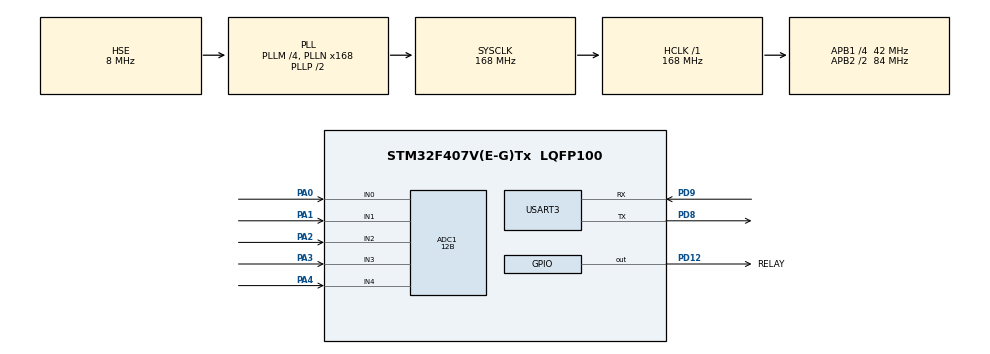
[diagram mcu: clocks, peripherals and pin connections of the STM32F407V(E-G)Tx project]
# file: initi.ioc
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ADC1.Channel-0\#ChannelRegularConversion=ADC_CHANNEL_0
ADC1.Channel-1\#ChannelRegularConversion=ADC_CHANNEL_1
ADC1.Channel-2\#ChannelRegularConversion=ADC_CHANNEL_2
ADC1.Channel-8\#ChannelRegularConversion=ADC_CHANNEL_3
ADC1.Channel-9\#ChannelRegularConversion=ADC_CHANNEL_4
ADC1.ClockPrescaler=ADC_CLOCK_SYNC_PCLK_DIV8
ADC1.ContinuousConvMode=ENABLE
ADC1.DMAContinuousRequests=ENABLE
ADC1.DataAlign=ADC_DATAALIGN_RIGHT
ADC1.DiscontinuousConvMode=DISABLE
ADC1.EOCSelection=ADC_EOC_SINGLE_CONV
ADC1.EnableAnalogWatchDog=false
ADC1.ExternalTrigConv=ADC_SOFTWARE_START
ADC1.ExternalTrigConvEdge=ADC_EXTERNALTRIGCONVEDGE_NONE
ADC1.InjNumberOfConversion=0
ADC1.NbrOfConversion=5
ADC1.NbrOfConversionFlag=1
ADC1.Rank-0\#ChannelRegularConversion=1
ADC1.Rank-1\#ChannelRegularConversion=2
ADC1.Rank-2\#ChannelRegularConversion=3
ADC1.Rank-8\#ChannelRegularConversion=4
ADC1.Rank-9\#ChannelRegularConversion=5
ADC1.Resolution=ADC_RESOLUTION_12B
ADC1.SamplingTime-0\#ChannelRegularConversion=ADC_SAMPLETIME_480CYCLES
ADC1.SamplingTime-1\#ChannelRegularConversion=ADC_SAMPLETIME_480CYCLES
ADC1.SamplingTime-2\#ChannelRegularConversion=ADC_SAMPLETIME_480CYCLES
ADC1.SamplingTime-8\#ChannelRegularConversion=ADC_SAMPLETIME_480CYCLES
ADC1.SamplingTime-9\#ChannelRegularConversion=ADC_SAMPLETIME_480CYCLES
ADC1.ScanConvMode=ENABLE
ADC1.master=1
Dma.ADC1.0.Direction=DMA_PERIPH_TO_MEMORY
Dma.ADC1.0.FIFOMode=DMA_FIFOMODE_DISABLE
Dma.ADC1.0.Instance=DMA2_Stream0
Dma.ADC1.0.MemDataAlignment=DMA_MDATAALIGN_HALFWORD
Dma.ADC1.0.MemInc=DMA_MINC_ENABLE
Dma.ADC1.0.Mode=DMA_CIRCULAR
Dma.ADC1.0.PeriphDataAlignment=DMA_PDATAALIGN_HALFWORD
Dma.ADC1.0.PeriphInc=DMA_PINC_DISABLE
Dma.ADC1.0.Priority=DMA_PRIORITY_LOW
Dma.Request0=ADC1
Mcu.Family=STM32F4
Mcu.Name=STM32F407V(E-G)Tx
Mcu.Package=LQFP100
NVIC.DMA2_Stream0_IRQn=true\:0\:0\:false\:false\:true\:false
NVIC.PriorityGroup=NVIC_PRIORITYGROUP_4
NVIC.TIM6_DAC_IRQn=true\:0\:0\:false\:false\:true\:true
NVIC.USART3_IRQn=true\:1\:0\:true\:false\:true\:true
PA0-WKUP.Signal=ADCx_IN0
PA1.Signal=ADCx_IN1
PA2.Signal=ADCx_IN2
PA3.Signal=ADCx_IN3
PA4.Signal=ADCx_IN4
PD12.GPIO_Label=RELAY
PD12.PinState=GPIO_PIN_SET
PD12.Signal=GPIO_Output
PD8.Mode=Asynchronous
PD8.Signal=USART3_TX
PD9.Mode=Asynchronous
PD9.Signal=USART3_RX
PH0-OSC_IN.Mode=HSE-External-Oscillator
PH0-OSC_IN.Signal=RCC_OSC_IN
PH1-OSC_OUT.Mode=HSE-External-Oscillator
PH1-OSC_OUT.Signal=RCC_OSC_OUT
ProjectManager.HeapSize=0x200
ProjectManager.StackSize=0x400
ProjectManager.TargetToolchain=MDK-ARM V5
RCC.48MHZClocksFreq_Value=84000000
RCC.AHBFreq_Value=168000000
RCC.APB1CLKDivider=RCC_HCLK_DIV4
RCC.APB1Freq_Value=42000000
RCC.APB1TimFreq_Value=84000000
RCC.APB2CLKDivider=RCC_HCLK_DIV2
RCC.APB2Freq_Value=84000000
RCC.APB2TimFreq_Value=168000000
RCC.CortexFreq_Value=168000000
RCC.HCLKFreq_Value=168000000
RCC.HSE_VALUE=8000000
RCC.HSI_VALUE=16000000
RCC.LSE_VALUE=32768
RCC.PLLM=4
RCC.PLLN=168
RCC.PLLSourceVirtual=RCC_PLLSOURCE_HSE
RCC.SYSCLKFreq_VALUE=168000000
RCC.SYSCLKSource=RCC_SYSCLKSOURCE_PLLCLK
RCC.VCOOutputFreq_Value=336000000
SH.ADCx_IN0.0=ADC1_IN0,IN0
SH.ADCx_IN1.0=ADC1_IN1,IN1
SH.ADCx_IN2.0=ADC1_IN2,IN2
SH.ADCx_IN3.0=ADC1_IN3,IN3
SH.ADCx_IN4.0=ADC1_IN4,IN4
TIM6.Period=20000
TIM6.Prescaler=41999
USART3.VirtualMode=VM_ASYNC
VP_TIM6_VS_ClockSourceINT.Mode=Enable_Timer
board=custom

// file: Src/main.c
/**
  ******************************************************************************
  * @file           : main.c
  * @brief          : Main program body
  ******************************************************************************
  ** This notice applies to any and all portions of this file
  * that are not between comment pairs USER CODE BEGIN and
  * USER CODE END. Other portions of this file, whether
  * inserted by the user or by software development tools
  * are owned by their respective copyright owners.
  *
  * COPYRIGHT(c) 2019 STMicroelectronics
  *
  * Redistribution and use in source and binary forms, with or without modification,
  * are permitted provided that the following conditions are met:
  *   1. Redistributions of source code must retain the above copyright notice,
  *      this list of conditions and the following disclaimer.
  *   2. Redistributions in binary form must reproduce the above copyright notice,
  *      this list of conditions and the following disclaimer in the documentation
  *      and/or other materials provided with the distribution.
  *   3. Neither the name of STMicroelectronics nor the names of its contributors
  *      may be used to endorse or promote products derived from this software
  *      without specific prior written permission.
  *
  * THIS SOFTWARE IS PROVIDED BY THE COPYRIGHT HOLDERS AND CONTRIBUTORS "AS IS"
  * AND ANY EXPRESS OR IMPLIED WARRANTIES, INCLUDING, BUT NOT LIMITED TO, THE
  * IMPLIED WARRANTIES OF MERCHANTABILITY AND FITNESS FOR A PARTICULAR PURPOSE ARE
  * DISCLAIMED. IN NO EVENT SHALL THE COPYRIGHT HOLDER OR CONTRIBUTORS BE LIABLE
  * FOR ANY DIRECT, INDIRECT, INCIDENTAL, SPECIAL, EXEMPLARY, OR CONSEQUENTIAL
  * DAMAGES (INCLUDING, BUT NOT LIMITED TO, PROCUREMENT OF SUBSTITUTE GOODS OR
  * SERVICES; LOSS OF USE, DATA, OR PROFITS; OR BUSINESS INTERRUPTION) HOWEVER
  * CAUSED AND ON ANY THEORY OF LIABILITY, WHETHER IN CONTRACT, STRICT LIABILITY,
  * OR TORT (INCLUDING NEGLIGENCE OR OTHERWISE) ARISING IN ANY WAY OUT OF THE USE
  * OF THIS SOFTWARE, EVEN IF ADVISED OF THE POSSIBILITY OF SUCH DAMAGE.
  *
  ******************************************************************************
  */
#include "main.h"
#include "stm32f4xx_hal.h"

ADC_HandleTypeDef hadc1;
DMA_HandleTypeDef hdma_adc1;

TIM_HandleTypeDef htim6;

UART_HandleTypeDef huart3;

/* USER CODE BEGIN PV */
/* Private variables ---------------------------------------------------------*/
//array in RAM for DMA-Controller to set values from ADC
volatile uint16_t adc_array[CHANNELS_NUMBER];
//buffer for messages of different length
uint8_t uart_rx_buf[UART_RX_BUF_SIZE];
/* USER CODE END PV */

void SystemClock_Config(void);
static void MX_GPIO_Init(void);
static void MX_DMA_Init(void);
static void MX_ADC1_Init(void);
static void MX_TIM6_Init(void);
static void MX_USART3_UART_Init(void);

/* USER CODE BEGIN PFP */
/* Private function prototypes -----------------------------------------------*/

/* USER CODE END PFP */

int main(void)
{

  /* MCU Configuration----------------------------------------------------------*/

  /* Reset of all peripherals, Initializes the Flash interface and the Systick. */
  HAL_Init();

  /* Configure the system clock */
  SystemClock_Config();

  /* Initialize all configured peripherals */
  MX_GPIO_Init();
  MX_DMA_Init();
  MX_ADC1_Init();
  MX_TIM6_Init();
  MX_USART3_UART_Init();
  /* USER CODE BEGIN 2 */
	//stat circular conversion
	HAL_ADC_Start_DMA(&hadc1, (uint32_t *) adc_array, CHANNELS_NUMBER);
	//enable IDLE interrupt to be able to detect the end of messages
	USART3->CR1 |= USART_CR1_IDLEIE;
	//start receiving to buffer
	HAL_UART_Receive_IT(&huart3, uart_rx_buf, UART_RX_BUF_SIZE);
  /* USER CODE END 2 */

  /* Infinite loop */
  while (1)
  {

  }

}

void SystemClock_Config(void)
{

  RCC_OscInitTypeDef RCC_OscInitStruct;
  RCC_ClkInitTypeDef RCC_ClkInitStruct;

    /**Configure the main internal regulator output voltage
    */
  __HAL_RCC_PWR_CLK_ENABLE();

  __HAL_PWR_VOLTAGESCALING_CONFIG(PWR_REGULATOR_VOLTAGE_SCALE1);

    /**Initializes the CPU, AHB and APB busses clocks
    */
  RCC_OscInitStruct.OscillatorType = RCC_OSCILLATORTYPE_HSE;
  RCC_OscInitStruct.HSEState = RCC_HSE_ON;
  RCC_OscInitStruct.PLL.PLLState = RCC_PLL_ON;
  RCC_OscInitStruct.PLL.PLLSource = RCC_PLLSOURCE_HSE;
  RCC_OscInitStruct.PLL.PLLM = 4;
  RCC_OscInitStruct.PLL.PLLN = 168;
  RCC_OscInitStruct.PLL.PLLP = RCC_PLLP_DIV2;
  RCC_OscInitStruct.PLL.PLLQ = 4;
  if (HAL_RCC_OscConfig(&RCC_OscInitStruct) != HAL_OK)
  {
    _Error_Handler(__FILE__, __LINE__);
  }

    /**Initializes the CPU, AHB and APB busses clocks
    */
  RCC_ClkInitStruct.ClockType = RCC_CLOCKTYPE_HCLK|RCC_CLOCKTYPE_SYSCLK
                              |RCC_CLOCKTYPE_PCLK1|RCC_CLOCKTYPE_PCLK2;
  RCC_ClkInitStruct.SYSCLKSource = RCC_SYSCLKSOURCE_PLLCLK;
  RCC_ClkInitStruct.AHBCLKDivider = RCC_SYSCLK_DIV1;
  RCC_ClkInitStruct.APB1CLKDivider = RCC_HCLK_DIV4;
  RCC_ClkInitStruct.APB2CLKDivider = RCC_HCLK_DIV2;

  if (HAL_RCC_ClockConfig(&RCC_ClkInitStruct, FLASH_LATENCY_5) != HAL_OK)
  {
    _Error_Handler(__FILE__, __LINE__);
  }

    /**Configure the Systick interrupt time
    */
  HAL_SYSTICK_Config(HAL_RCC_GetHCLKFreq()/1000);

    /**Configure the Systick
    */
  HAL_SYSTICK_CLKSourceConfig(SYSTICK_CLKSOURCE_HCLK);

  /* SysTick_IRQn interrupt configuration */
  HAL_NVIC_SetPriority(SysTick_IRQn, 0, 0);
}

/* ADC1 init function */
static void MX_ADC1_Init(void)
{

  ADC_ChannelConfTypeDef sConfig;

    /**Configure the global features of the ADC (Clock, Resolution, Data Alignment and number of conversion)
    */
  hadc1.Instance = ADC1;
  hadc1.Init.ClockPrescaler = ADC_CLOCK_SYNC_PCLK_DIV8;
  hadc1.Init.Resolution = ADC_RESOLUTION_12B;
  hadc1.Init.ScanConvMode = ENABLE;
  hadc1.Init.ContinuousConvMode = ENABLE;
  hadc1.Init.DiscontinuousConvMode = DISABLE;
  hadc1.Init.ExternalTrigConvEdge = ADC_EXTERNALTRIGCONVEDGE_NONE;
  hadc1.Init.ExternalTrigConv = ADC_SOFTWARE_START;
  hadc1.Init.DataAlign = ADC_DATAALIGN_RIGHT;
  hadc1.Init.NbrOfConversion = 5;
  hadc1.Init.DMAContinuousRequests = ENABLE;
  hadc1.Init.EOCSelection = ADC_EOC_SINGLE_CONV;
  if (HAL_ADC_Init(&hadc1) != HAL_OK)
  {
    _Error_Handler(__FILE__, __LINE__);
  }

    /**Configure for the selected ADC regular channel its corresponding rank in the sequencer and its sample time.
    */
  sConfig.Channel = ADC_CHANNEL_0;
  sConfig.Rank = 1;
  sConfig.SamplingTime = ADC_SAMPLETIME_480CYCLES;
  if (HAL_ADC_ConfigChannel(&hadc1, &sConfig) != HAL_OK)
  {
    _Error_Handler(__FILE__, __LINE__);
  }

    /**Configure for the selected ADC regular channel its corresponding rank in the sequencer and its sample time.
    */
  sConfig.Channel = ADC_CHANNEL_1;
  sConfig.Rank = 2;
  if (HAL_ADC_ConfigChannel(&hadc1, &sConfig) != HAL_OK)
  {
    _Error_Handler(__FILE__, __LINE__);
  }

    /**Configure for the selected ADC regular channel its corresponding rank in the sequencer and its sample time.
    */
  sConfig.Channel = ADC_CHANNEL_2;
  sConfig.Rank = 3;
  if (HAL_ADC_ConfigChannel(&hadc1, &sConfig) != HAL_OK)
  {
    _Error_Handler(__FILE__, __LINE__);
  }

    /**Configure for the selected ADC regular channel its corresponding rank in the sequencer and its sample time.
    */
  sConfig.Channel = ADC_CHANNEL_3;
  sConfig.Rank = 4;
  if (HAL_ADC_ConfigChannel(&hadc1, &sConfig) != HAL_OK)
  {
    _Error_Handler(__FILE__, __LINE__);
  }

    /**Configure for the selected ADC regular channel its corresponding rank in the sequencer and its sample time.
    */
  sConfig.Channel = ADC_CHANNEL_4;
  sConfig.Rank = 5;
  if (HAL_ADC_ConfigChannel(&hadc1, &sConfig) != HAL_OK)
  {
    _Error_Handler(__FILE__, __LINE__);
  }

}

/* TIM6 init function */
static void MX_TIM6_Init(void)
{

  TIM_MasterConfigTypeDef sMasterConfig;

  htim6.Instance = TIM6;
  htim6.Init.Prescaler = 41999;
  htim6.Init.CounterMode = TIM_COUNTERMODE_UP;
  htim6.Init.Period = 20000;
  if (HAL_TIM_Base_Init(&htim6) != HAL_OK)
  {
    _Error_Handler(__FILE__, __LINE__);
  }

  sMasterConfig.MasterOutputTrigger = TIM_TRGO_RESET;
  sMasterConfig.MasterSlaveMode = TIM_MASTERSLAVEMODE_DISABLE;
  if (HAL_TIMEx_MasterConfigSynchronization(&htim6, &sMasterConfig) != HAL_OK)
  {
    _Error_Handler(__FILE__, __LINE__);
  }

}

/* USART3 init function */
static void MX_USART3_UART_Init(void)
{

  huart3.Instance = USART3;
  huart3.Init.BaudRate = 115200;
  huart3.Init.WordLength = UART_WORDLENGTH_8B;
  huart3.Init.StopBits = UART_STOPBITS_1;
  huart3.Init.Parity = UART_PARITY_NONE;
  huart3.Init.Mode = UART_MODE_TX_RX;
  huart3.Init.HwFlowCtl = UART_HWCONTROL_NONE;
  huart3.Init.OverSampling = UART_OVERSAMPLING_16;
  if (HAL_UART_Init(&huart3) != HAL_OK)
  {
    _Error_Handler(__FILE__, __LINE__);
  }

}

static void MX_DMA_Init(void)
{
  /* DMA controller clock enable */
  __HAL_RCC_DMA2_CLK_ENABLE();

  /* DMA interrupt init */
  /* DMA2_Stream0_IRQn interrupt configuration */
  HAL_NVIC_SetPriority(DMA2_Stream0_IRQn, 0, 0);
  HAL_NVIC_EnableIRQ(DMA2_Stream0_IRQn);

}

/** Configure pins as
        * Analog
        * Input
        * Output
        * EVENT_OUT
        * EXTI
*/
static void MX_GPIO_Init(void)
{

  GPIO_InitTypeDef GPIO_InitStruct;

  /* GPIO Ports Clock Enable */
  __HAL_RCC_GPIOH_CLK_ENABLE();
  __HAL_RCC_GPIOA_CLK_ENABLE();
  __HAL_RCC_GPIOD_CLK_ENABLE();

  /*Configure GPIO pin Output Level */
  HAL_GPIO_WritePin(RELAY_GPIO_Port, RELAY_Pin, GPIO_PIN_SET);

  /*Configure GPIO pin : RELAY_Pin */
  GPIO_InitStruct.Pin = RELAY_Pin;
  GPIO_InitStruct.Mode = GPIO_MODE_OUTPUT_PP;
  GPIO_InitStruct.Pull = GPIO_NOPULL;
  GPIO_InitStruct.Speed = GPIO_SPEED_FREQ_LOW;
  HAL_GPIO_Init(RELAY_GPIO_Port, &GPIO_InitStruct);

}

void _Error_Handler(char *file, int line)
{
  while(1)
  {
  }
}

/************************ (C) COPYRIGHT STMicroelectronics *****END OF FILE****/
